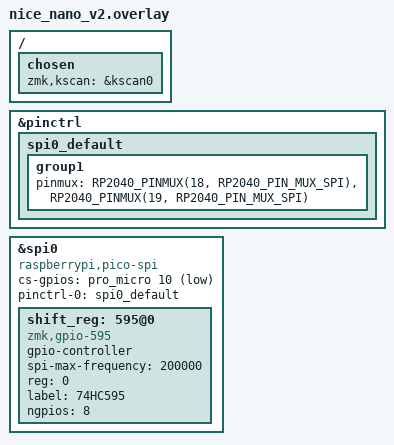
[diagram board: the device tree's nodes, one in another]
#include <dt-bindings/led/led.h>

&pinctrl {
    spi0_default: spi0_default {
        group1 {
            pinmux = <RP2040_PINMUX(18, RP2040_PIN_MUX_SPI)>,
                     <RP2040_PINMUX(19, RP2040_PIN_MUX_SPI)>;
        };
    };
};

&spi0 {
    compatible = "raspberrypi,pico-spi";
    status = "okay";
    cs-gpios = <&pro_micro 10 GPIO_ACTIVE_LOW>;
    pinctrl-0 = <&spi0_default>;
    pinctrl-names = "default";

    shift_reg: 595@0 {
        compatible = "zmk,gpio-595";
        status = "okay";
        gpio-controller;
        spi-max-frequency = <200000>;
        reg = <0>;
        label = "74HC595";
        #gpio-cells = <2>;
        ngpios = <8>;
    };
};

/ {
    chosen {
        zmk,kscan = &kscan0;
    };
};
